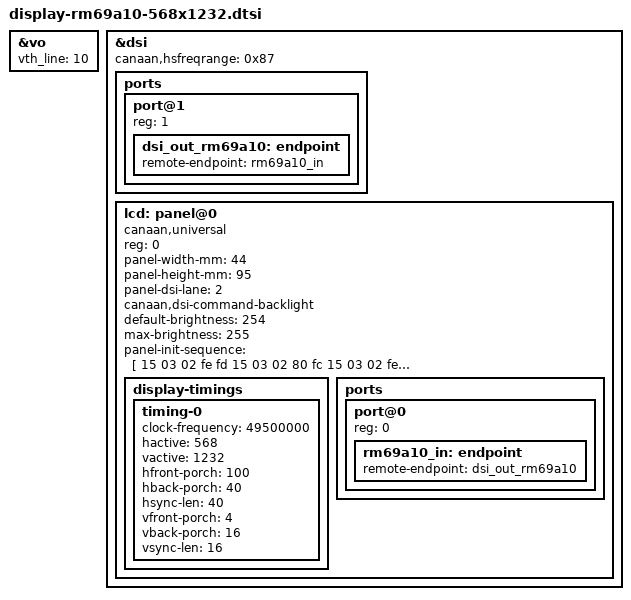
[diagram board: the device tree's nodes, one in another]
// SPDX-License-Identifier: GPL-2.0
// RM69A10 4.1" 568x1232 AMOLED, as fitted to the LILYGO T-Display-K230.
//
// Structure follows display-st7701-480x800.dtsi exactly: the panel is a
// DSI device inside &dsi, labelled `lcd` so a board .dts can attach its
// reset and backlight GPIOs, with an endpoint graph back to &dsi.
//
// The init sequence is transcribed from the vendor's working RT-Smart
// driver -- all 20 commands, 297 payload bytes. See
// docs/evidence/rm69a10-init-sequence.md, which cites a source line per
// command.
//
// UNVERIFIED: none of this has been run on hardware.

&vo {
	// intr_line from connector_info_list[] for this panel.
	// 10, matching every Canaan board dts in the vendor tree
	// (k230-canmv-01studio*.dts, -dongshanpi.dts, ...). This was 9,
	// which docs/evidence/dts-divergence.md recorded as a divergence
	// without a reason -- and there is no vth_line anywhere in
	// LilyGO's RT-Smart tree to have taken 9 from. An ungrounded
	// divergence in a video timing parameter, on a panel that does not
	// light, is not worth keeping.
	vth_line = <10>;
};

&dsi {
	// DSI PHY HS timing calibration band (DWC D-PHY register 0x44).
	//
	// The driver hardcoded 0x96 -- its own TXPHY_445_5_HS_FREQ, the band
	// for 445.5 Mbps -- regardless of the rate actually run. We run 594
	// Mbps. Measured like-for-like, same board, same camera position, only
	// this value changed:
	//
	//            motion std   span   frame-to-frame mean / max   jumps>2px
	//   0x96        0.68 px   4.50            0.26 / 2.33             1
	//   0x87        0.35 px   1.92            0.02 / 0.35             0
	//
	// Frame-to-frame jitter drops thirteenfold and the visible roll stops.
	// See docs/evidence/dsi-hsfreqrange-hardcoded.md.
	//
	// The byte is 0x80 | code. Against the standard Synopsys hsfreqrange
	// table the codes mean 0x16 = 450..499 Mbps, 0x07 = 500..549,
	// 0x17 = 550..599. By that table 594 Mbps should be 0x17, and 0x17
	// BLANKS the panel outright -- tried, dark screen. 0x07 is what
	// actually works, so this SoC's bands sit one step below the standard
	// table. That is an empirical result, not a datasheet one: the value
	// is here because it was measured, and the reasoning that predicted
	// 0x17 was wrong.
	canaan,hsfreqrange = <0x87>;

	ports {
		port@1 {
			reg = <1>;
			dsi_out_rm69a10: endpoint {
				remote-endpoint = <&rm69a10_in>;
			};
		};
	};

	lcd: panel@0 {
		compatible = "canaan,universal";
		reg = <0>;

		// DIVERGENCE: the reference puts PIXEL COUNTS in these (480/800 for
		// a 480x800 panel). These are real millimetres, computed from the
		// stated 4.1" diagonal at 568x1232 -- not measured. Only affects the
		// DPI the connector reports.
		panel-width-mm = <44>;
		panel-height-mm = <95>;

		panel-dsi-lane = <2>;

		// the-panel-brightness-is-adjustable: opt this panel into a
		// DSI-command backlight (MIPI_DCS_SET_DISPLAY_BRIGHTNESS,
		// 0x51, gated by MIPI_DCS_WRITE_CONTROL_DISPLAY, 0x53), driven
		// by drivers/gpu/drm/panel/panel-canaan-universal.c. Property
		// names match LILYGO's own k230_bsp patch
		// 0049-drm-panel-canaan-universal-add-rm69a10-dsi-backlight.patch.
		// default-brightness matches the fixed 0xFE this board has
		// always shown (see panel-init-sequence's SET_DISPLAY_BRIGHTNESS
		// below), so a fresh boot looks unchanged until someone moves
		// the Settings brightness stepper.
		canaan,dsi-command-backlight;
		default-brightness = <254>;
		max-brightness = <255>;

		// framing: data_type, delay_ms, payload_length, payload...
		// delay is u8 MILLIseconds. The vendor waits 300us after 0x11 and
		// 100us after 0x29; neither is expressible, so both become 1 ms,
		// which is longer than the vendor waits.
		panel-init-sequence = [
			15 03 02 fe fd   /* Raydium page select: FE=FD */
			15 03 02 80 fc   /* page FC */
			15 03 02 fe 00   /* back to user page 00 */
			39 03 05 2a 00 00 02 37   /* column address 0..0x237 (567) */
			39 03 05 2b 00 00 04 cf   /* page address 0..0x4cf (1231) */
			/* The vendor sets a partial area here and enters partial
			 * display mode (0x12). Reproducing that lit the panel but
			 * the image glitches, which is what a restricted partial
			 * area looks like when the VO is streaming a full frame
			 * into it. We want the whole 568x1232 panel, so: skip the
			 * partial-area writes and use ENTER_NORMAL_MODE instead.
			 * If this regresses, the vendor's 31/30/12 block is above
			 * in the history and its VO differences are catalogued in
			 * docs/evidence/rtsmart-panel-bringup.md. */
			15 03 02 13 00   /* enter normal mode (was 31/30 + 12) */
			15 03 02 35 00   /* tearing effect on */
			15 05 02 51 fe   /* SET_DISPLAY_BRIGHTNESS 0xFE, then 2ms */
			05 7b 01 11   /* sleep out, then 120ms */
			05 03 01 29   /* display on */
			15 03 02 3a 77   /* pixel format 0x77 */
		];

		// From connector_info_list[] in mpi_connector.c:
		//   pclk 39600 kHz, phyclk 475200 kHz, 2 lanes, burst mode
		// 39.6 MHz / (788 x 1268) = 39.63 Hz. The vendor enum is named
		// 60FPS and is wrong; the numbers are self-consistent.
		display-timings {
			timing-0 {
				/* LILYGO's own Linux kernel queue for this board,
				 * patch 0031: 49.5 MHz, htotal 748, vtotal 1268
				 * = 52.19 Hz. We had RT-Smart's 39.6 MHz / 39.63 Hz,
				 * which is the lowest refresh any implementation of
				 * this panel uses -- and its enum is named _60FPS,
				 * so even the vendor table looks mislabelled.
				 *
				 * An AMOLED emits in per-frame pulses, so sub-45 Hz
				 * shows as flicker on a completely static image,
				 * which is exactly the symptom. LILYGO's 0042 says
				 * they moved off the original timing for "the
				 * low-refresh stutter seen at the original timing" --
				 * the only first-hand artifact report on this board.
				 */
				clock-frequency = <49500000>;
				hactive = <568>;
				vactive = <1232>;
				hfront-porch = <100>;
				hback-porch = <40>;
				hsync-len = <40>;
				vfront-porch = <4>;
				vback-porch = <16>;
				vsync-len = <16>;
			};
		};

		ports {
			#address-cells = <1>;
			#size-cells = <0>;

			port@0 {
				reg = <0>;
				rm69a10_in: endpoint {
					remote-endpoint = <&dsi_out_rm69a10>;
				};
			};
		};
	};
};
